# STM32G061 register map
File version: 1.4
CPU: CM0 r0p1, little endian, MPU, no FPU, 2 interrupt priority bits
Registers are 32-bit, read-write, reset 0x0 unless marked. A register's access mark holds for its fields unless they carry their own. Offsets are from the block's base; [hi:lo] are bit positions; {n}, {i} and the like mark numbered series.

## IWDG — Independent watchdog
Base 0x40003000
0x00 KR 16-bit wo — Key register
  [15:0] KEY — Key value (write only, read 0x0000)
    0x5555=Unlock (Enable access to PR, RLR and WINR registers); 0xAAAA=Feed watchdog with RLR register value; 0xCCCC=Start the watchdog
0x04 PR 16-bit — Prescaler register
  [2:0] PR — Prescaler divider These bits are write access protected see . They are written by software to select the prescaler divider feeding the counter clock. PVU bit of the must be reset in order to be able to change the prescaler divider. Note: Reading this register returns the prescaler value from the VDD voltage domain. This value may not be up to date/valid if a write operation to this register is ongoing. For this reason the value read from this register is valid only when the PVU bit in the status register (IWDG_SR) is reset.
    0=DivideBy4 (Divider /4); 1=DivideBy8 (Divider /8); 2=DivideBy16 (Divider /16); 3=DivideBy32 (Divider /32); 4=DivideBy64 (Divider /64); 5=DivideBy128 (Divider /128); other=DivideBy256 (Divider /256)
0x08 RLR 16-bit reset 0xFFF — Reload register
  [11:0] RL — Watchdog counter reload value
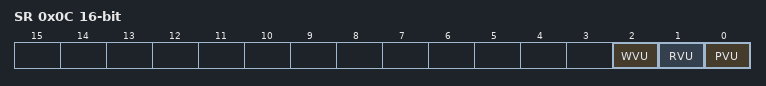
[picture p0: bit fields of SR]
0x0C SR 16-bit ro — Status register
  [2] WVU — Watchdog counter window value update This bit is set by hardware to indicate that an update of the window value is ongoing. It is reset by hardware when the reload value update operation is completed in the VDD voltage domain (takes up to five LSI cycles). Window value can be updated only when WVU bit is reset.
  [1] RVU — Watchdog counter reload value update This bit is set by hardware to indicate that an update of the reload value is ongoing. It is reset by hardware when the reload value update operation is completed in the VDD voltage domain (takes up to five LSI cycles). Reload value can be updated only when RVU bit is reset.
  [0] PVU — Watchdog prescaler value update This bit is set by hardware to indicate that an update of the prescaler value is ongoing. It is reset by hardware when the prescaler update operation is completed in the VDD voltage domain (takes up to five LSI cycles). Prescaler value can be updated only when PVU bit is reset.
0x10 WINR 16-bit reset 0xFFF — Window register
  [11:0] WIN — Watchdog counter window value

## PWR — Power control
Base 0x40007000
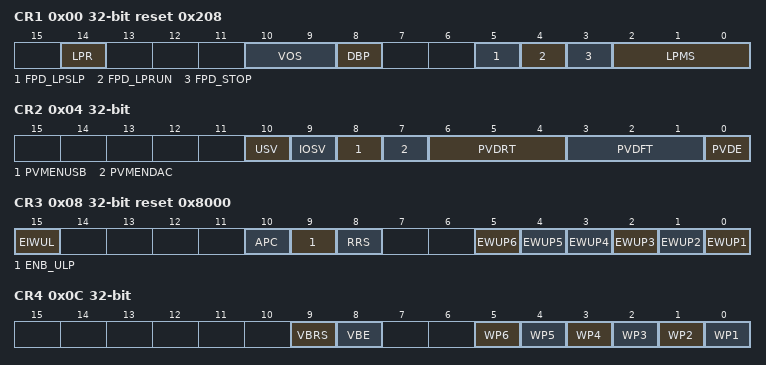
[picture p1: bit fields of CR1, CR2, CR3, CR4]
0x00 CR1 reset 0x208 — Power control register 1
  [14] LPR — Low-power run
  [10:9] VOS — Voltage scaling range selection
  [8] DBP — Disable backup domain write protection
  [5] FPD_LPSLP — Flash memory powered down during Low-power sleep mode
  [4] FPD_LPRUN — Flash memory powered down during Low-power run mode
  [3] FPD_STOP — Flash memory powered down during Stop mode
  [2:0] LPMS — Low-power mode selection
0x04 CR2 — Power control register 2
  [10] USV
  [9] IOSV
  [8] PVMENUSB
  [7] PVMENDAC
  [6:4] PVDRT — Power voltage detector rising threshold selection
  [3:1] PVDFT — Power voltage detector falling threshold selection
  [0] PVDE — Power voltage detector enable
0x08 CR3 reset 0x8000 — Power control register 3
  [15] EIWUL — Enable internal wakeup line
  [10] APC — Apply pull-up and pull-down configuration
  [9] ENB_ULP — Ultra-low-power enable
  [8] RRS — SRAM retention in Standby mode
  [5] EWUP6 — Enable WKUP6 wakeup pin
  [4] EWUP5 — Enable WKUP5 wakeup pin
  [n-1] EWUP{n} (n=1..4) — Enable Wakeup pin WKUP{n}
0x0C CR4 — Power control register 4
  [9] VBRS — VBAT battery charging resistor selection
  [8] VBE — VBAT battery charging enable
  [5] WP6 — WKUP6 wakeup pin polarity
  [n-1] WP{n} (n=1..5) — Wakeup pin WKUP{n} polarity
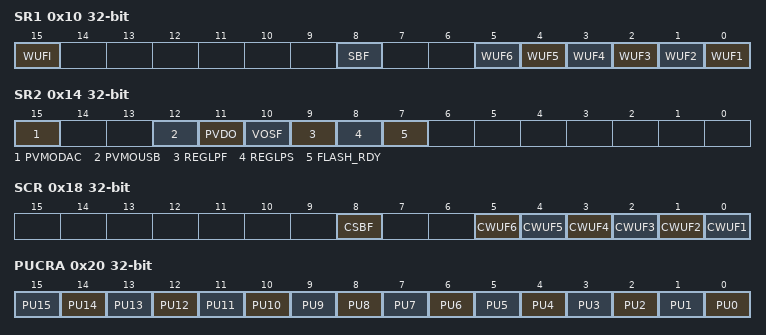
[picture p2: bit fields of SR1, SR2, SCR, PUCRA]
0x10 SR1 ro — Power status register 1
  [15] WUFI — Wakeup flag internal
  [8] SBF — Standby flag
  [n-1] WUF{n} (n=1..6) — Wakeup flag {n}
0x14 SR2 ro — Power status register 2
  [15] PVMODAC — VDDA monitoring output flag
  [12] PVMOUSB — USB supply voltage monitoring output flag
  [11] PVDO — Power voltage detector output
  [10] VOSF — Voltage scaling flag
  [9] REGLPF — Low-power regulator flag
  [8] REGLPS — Low-power regulator started
  [7] FLASH_RDY — Flash ready flag
0x18 SCR wo — Power status clear register
  [8] CSBF — Clear standby flag
  [n-1] CWUF{n} (n=1..6) — Clear wakeup flag {n}
0x20 PUCRA — Power Port A pull-up control register
  [n] PU{n} (n=0..15) — Port A pull-up bit y (y=0..15)
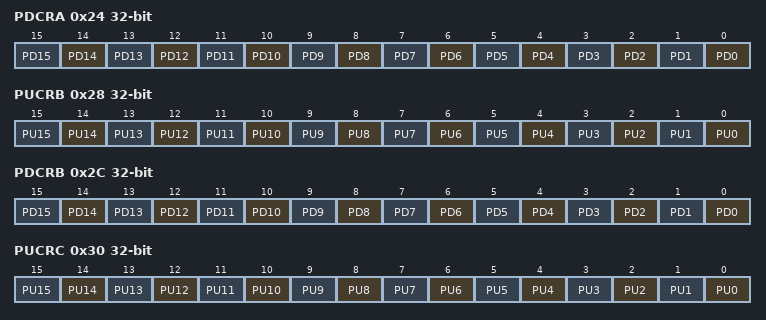
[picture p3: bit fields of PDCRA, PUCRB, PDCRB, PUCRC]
0x24 PDCRA — Power Port A pull-down control register
  [n] PD{n} (n=0..15) — Port A pull-down bit y (y=0..15)
0x28 PUCRB — Power Port B pull-up control register
  [n] PU{n} (n=0..15) — Port B pull-up bit y (y=0..15)
0x2C PDCRB — Power Port B pull-down control register
  [n] PD{n} (n=0..15) — Port B pull-down bit y (y=0..15)
0x30 PUCRC — Power Port C pull-up control register
  [n] PU{n} (n=0..15) — Port C pull-up bit y (y=0..15)
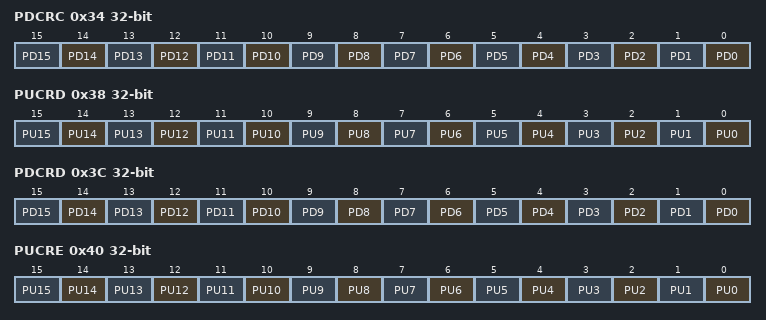
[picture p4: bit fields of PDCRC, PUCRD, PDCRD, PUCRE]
0x34 PDCRC — Power Port C pull-down control register
  [n] PD{n} (n=0..15) — Port C pull-down bit y (y=0..15)
0x38 PUCRD — Power Port D pull-up control register
  [n] PU{n} (n=0..15) — Port D pull-up bit y (y=0..15)
0x3C PDCRD — Power Port D pull-down control register
  [n] PD{n} (n=0..15) — Port D pull-down bit y (y=0..15)
0x40 PUCRE — Power Port E pull-UP control register
  [n] PU{n} (n=0..15) — Port E pull-up bit y (y=0..15)
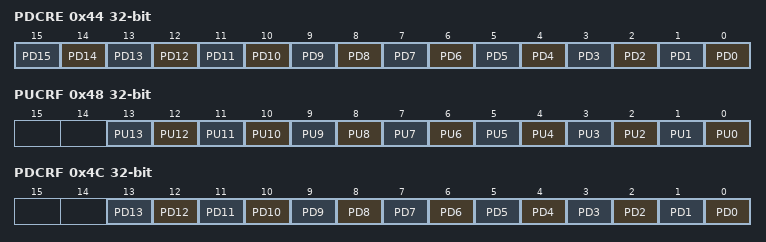
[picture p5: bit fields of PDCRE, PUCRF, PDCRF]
0x44 PDCRE — Power Port E pull-down control register
  [n] PD{n} (n=0..15) — Port E pull-down bit y (y=0..15)
0x48 PUCRF — Power Port F pull-up control register
  [n] PU{n} (n=0..13) — Port F pull-up bit y (y=0..15)
0x4C PDCRF — Power Port F pull-down control register
  [n] PD{n} (n=0..13) — Port F pull-down bit y (y=0..15)
